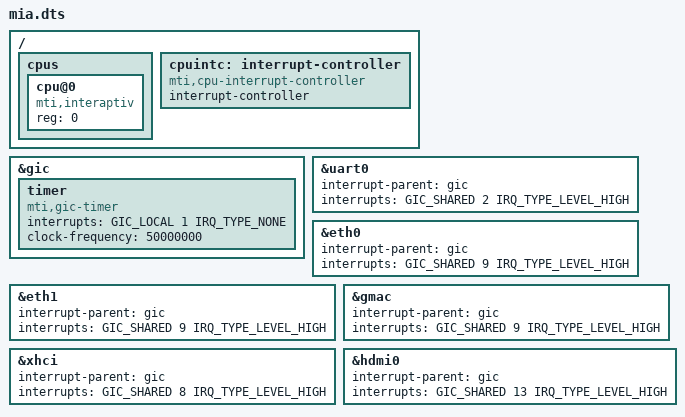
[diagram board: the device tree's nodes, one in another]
/*
 * Realtek Semiconductor Corp.
 *
 * Device Tree Structure
 *
 * Tony Wu (tonywu@realtek.com)
 */

/dts-v1/;

#include <dt-bindings/interrupt-controller/mips-gic.h>
#include "sheipa.dtsi"

/ {
	#address-cells = <1>;
	#size-cells = <1>;

	cpus {
		#address-cells = <1>;
		#size-cells = <0>;

		cpu@0 {
			compatible = "mti,interaptiv";
			device_type = "cpu";
			reg = <0>;
		};
	};

	cpuintc: interrupt-controller {
		#address-cells = <0>;
		#interrupt-cells = <1>;
		interrupt-controller;
		compatible = "mti,cpu-interrupt-controller";
	};

};

&gic {
	timer {
		compatible = "mti,gic-timer";
		interrupts = <GIC_LOCAL 1 IRQ_TYPE_NONE>;
		clock-frequency = <50000000>;
	};
};

&uart0 {
	interrupt-parent = <&gic>;
	interrupts = <GIC_SHARED 2 IRQ_TYPE_LEVEL_HIGH>;
};

&eth0 {
	interrupt-parent = <&gic>;
	interrupts = <GIC_SHARED 9 IRQ_TYPE_LEVEL_HIGH>;
};

&eth1 {
	interrupt-parent = <&gic>;
	interrupts = <GIC_SHARED 9 IRQ_TYPE_LEVEL_HIGH>;
};

&gmac {
	interrupt-parent = <&gic>;
	interrupts = <GIC_SHARED 9 IRQ_TYPE_LEVEL_HIGH>;
};

&xhci {
	interrupt-parent = <&gic>;
	interrupts = <GIC_SHARED 8 IRQ_TYPE_LEVEL_HIGH>;
};

&hdmi0 {
	interrupt-parent = <&gic>;
	interrupts = <GIC_SHARED 13 IRQ_TYPE_LEVEL_HIGH>;
};
